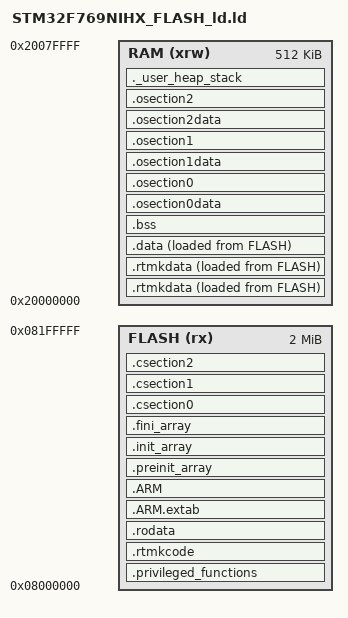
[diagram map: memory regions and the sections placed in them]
/*
******************************************************************************
**
** @file        : LinkerScript.ld
**
** @author      : Auto-generated by STM32CubeIDE
**
**  Abstract    : Linker script for STM32F769I-EVAL Board embedding STM32F769NIHx Device from stm32f7 series
**                      2048KBytes FLASH
**                      512KBytes RAM
**
**                Set heap size, stack size and stack location according
**                to application requirements.
**
**                Set memory bank area and size if external memory is used
**
**  Target      : STMicroelectronics STM32
**
**  Distribution: The file is distributed as is, without any warranty
**                of any kind.
**
******************************************************************************
** @attention
**
** Copyright (c) 2025 STMicroelectronics.
** All rights reserved.
**
** This software is licensed under terms that can be found in the LICENSE file
** in the root directory of this software component.
** If no LICENSE file comes with this software, it is provided AS-IS.
**
******************************************************************************
*/

/* Entry Point */
ENTRY(Reset_Handler)

/* Memories definition */
MEMORY
{
  RAM    (xrw)    : ORIGIN = 0x20000000,   LENGTH = 512K
  FLASH    (rx)    : ORIGIN = 0x8000000,   LENGTH = 2048K
}

/* Highest address of the user mode stack */
_estack = ORIGIN(RAM) + LENGTH(RAM); /* end of "RAM" Ram type memory */

_Min_Heap_Size = 0x400; /* required amount of heap */
_Min_Stack_Size = 0x400; /* required amount of stack */

__privileged_functions_region_size__ = 0x100000;  /* 1 MB */
__privileged_functions_region_end__  = ORIGIN(FLASH) + __privileged_functions_region_size__;

__rtmk_code_region_size__ = 0x4000;  /* 16 KB */
__rtmk_code_region_end__  = __privileged_functions_region_end__ + __rtmk_code_region_size__;

__rtmkdata_region_size__ = 0x2000;             /* 8 KB */
__rtmk_data_region_end__  =  ORIGIN(RAM) + __rtmkdata_region_size__;

/* Sections */
SECTIONS
{
  .privileged_functions :
  {
     . = ALIGN(4);
     KEEP(*(.isr_vector)) /* Startup code */
    . = ALIGN(4);
    *(.text)           /* .text sections (code) */
    *(.text*)          /* .text* sections (code) */
    *(.glue_7)         /* glue arm to thumb code */
    *(.glue_7t)        /* glue thumb to arm code */
    *(.eh_frame)
    KEEP (*(.init))
    KEEP (*(.fini))
    . = ALIGN(4);
   . = __privileged_functions_region_end__;
    _etext = .;        /* define a global symbols at end of code */

  } >FLASH

    .rtmkcode :
  {
    _srtmkcode = .;
    . = ALIGN(4);
    *libc_a*:(.text*)
    *libc.a:(.text*)
    *libm.a:(.text*)
    *libstdc++.a:(.text*)
    *(.rtmkcode)           /* .text sections (code) */
    *(.rtmkcode*)          /* .text* sections (code) */
    *(.glue_7)         /* glue arm to thumb code */
    *(.glue_7t)        /* glue thumb to arm code */
    *(.eh_frame)
    KEEP (*(.init))
    KEEP (*(.fini))

    . = ALIGN(4);
    _etext = .;        /* define a global symbols at end of code */
    _ertmkcode = .;
    . = __rtmk_code_region_end__;
  } >FLASH


  .rtmkdata : 
  { 
      _srtmkdata  = .;      /* start address symbol */
      _srtmkdata2 = .;
      . = ALIGN(4);
      *(privileged_data)
      *(.rtmkdata)         /* all objects with section ".rtmkdata" */
      . = ALIGN(4);
      _ertmkdata = .;      /* end address symbol */
      . = __rtmk_data_region_end__;
      _szrtmkdata = _ertmkdata - _srtmkdata;
  } >RAM AT> FLASH

  _lrtmkdata = LOADADDR(.rtmkdata);

  /* Constant data into "FLASH" Rom type memory */
  .rodata :
  {
    . = ALIGN(4);
    *(.rodata)         /* .rodata sections (constants, strings, etc.) */
    *(.rodata*)        /* .rodata* sections (constants, strings, etc.) */
    . = ALIGN(4);
  } >FLASH

  .ARM.extab : /* The "READONLY" keyword is only supported in GCC11 and later, remove it if using GCC10 or earlier. */
  {
    . = ALIGN(4);
    *(.ARM.extab* .gnu.linkonce.armextab.*)
    . = ALIGN(4);
  } >FLASH

  .ARM : /* The "READONLY" keyword is only supported in GCC11 and later, remove it if using GCC10 or earlier. */
  {
    . = ALIGN(4);
    __exidx_start = .;
    *(.ARM.exidx*)
    __exidx_end = .;
    . = ALIGN(4);
  } >FLASH

  .preinit_array : /* The "READONLY" keyword is only supported in GCC11 and later, remove it if using GCC10 or earlier. */
  {
    . = ALIGN(4);
    PROVIDE_HIDDEN (__preinit_array_start = .);
    KEEP (*(.preinit_array*))
    PROVIDE_HIDDEN (__preinit_array_end = .);
    . = ALIGN(4);
  } >FLASH

  .init_array : /* The "READONLY" keyword is only supported in GCC11 and later, remove it if using GCC10 or earlier. */
  {
    . = ALIGN(4);
    PROVIDE_HIDDEN (__init_array_start = .);
    KEEP (*(SORT(.init_array.*)))
    KEEP (*(.init_array*))
    PROVIDE_HIDDEN (__init_array_end = .);
    . = ALIGN(4);
  } >FLASH

  .fini_array : /* The "READONLY" keyword is only supported in GCC11 and later, remove it if using GCC10 or earlier. */
  {
    . = ALIGN(4);
    PROVIDE_HIDDEN (__fini_array_start = .);
    KEEP (*(SORT(.fini_array.*)))
    KEEP (*(.fini_array*))
    PROVIDE_HIDDEN (__fini_array_end = .);
    . = ALIGN(4);
  } >FLASH

  .rtmkdata :
  {
      _srtmkdata = .;      /* start address symbol */
      *(.rtmkdata)         /* all objects with section ".rtmkdata" */
      _ertmkdata = .;      /* end address symbol */
  } >RAM AT> FLASH

  _lrtmkdata = LOADADDR(.rtmkdata);

  /* Used by the startup to initialize data */
  _sidata = LOADADDR(.data);

  /* Initialized data sections into "RAM" Ram type memory */
  .data :
  {
    . = ALIGN(4);
    _sdata = .;        /* create a global symbol at data start */
    *(.data)           /* .data sections */
    *(.data*)          /* .data* sections */
    *(.RamFunc)        /* .RamFunc sections */
    *(.RamFunc*)       /* .RamFunc* sections */

    . = ALIGN(4);
    _edata = .;        /* define a global symbol at data end */

  } >RAM AT> FLASH


  /* Uninitialized data section into "RAM" Ram type memory */
  . = ALIGN(4);
  .bss :
  {
    /* This is used by the startup in order to initialize the .bss section */
    _sbss = .;         /* define a global symbol at bss start */
    __bss_start__ = _sbss;
    *(.bss)
    *(.bss*)
    *(COMMON)

    . = ALIGN(4);
    _ebss = .;         /* define a global symbol at bss end */
    __bss_end__ = _ebss;
  } >RAM

COMPARTMENT_DATA_START = LOADADDR(.data) + SIZEOF(.data); 
COMPARTMENT_DATA_COUNTER = 0;
  .osection0data : AT (COMPARTMENT_DATA_START + COMPARTMENT_DATA_COUNTER) 
  { . = ALIGN(4); 
		_sosection0data = .; 
  *(.osection0data)		   /* .data sections. */
  . = ALIGN(4); 
  _eosection0data = .;
} > RAM 
COMPARTMENT_DATA_COUNTER = COMPARTMENT_DATA_COUNTER + SIZEOF(.osection0data); 
_sosection0datal = LOADADDR(.osection0data);
  .osection0 :
  {
	  . = ALIGN(4);
	  _sosection0 = .;
	  *(.osection0)
	  . = ALIGN(4);
	  _eosection0 = .;
_szosection0 = _eosection0 - _sosection0data;  }  > RAM 
  .osection1data : AT (COMPARTMENT_DATA_START + COMPARTMENT_DATA_COUNTER) 
  { . = ALIGN(4); 
		_sosection1data = .; 
  *(.osection1data)		   /* .data sections. */
  . = ALIGN(4); 
  _eosection1data = .;
} > RAM 
COMPARTMENT_DATA_COUNTER = COMPARTMENT_DATA_COUNTER + SIZEOF(.osection1data); 
_sosection1datal = LOADADDR(.osection1data);
  .osection1 :
  {
	  . = ALIGN(4);
	  _sosection1 = .;
	  *(.osection1)
	  . = ALIGN(4);
	  _eosection1 = .;
_szosection1 = _eosection1 - _sosection1data;  }  > RAM 
  .osection2data : AT (COMPARTMENT_DATA_START + COMPARTMENT_DATA_COUNTER) 
  { . = ALIGN(4); 
		_sosection2data = .; 
  *(.osection2data)		   /* .data sections. */
  . = ALIGN(4); 
  _eosection2data = .;
} > RAM 
COMPARTMENT_DATA_COUNTER = COMPARTMENT_DATA_COUNTER + SIZEOF(.osection2data); 
_sosection2datal = LOADADDR(.osection2data);
  .osection2 :
  {
	  . = ALIGN(4);
	  _sosection2 = .;
	  *(.osection2)
	  . = ALIGN(4);
	  _eosection2 = .;
_szosection2 = _eosection2 - _sosection2data;  }  > RAM 
	
CODE_SECTIONS_START = LOADADDR(.osection2data) + SIZEOF(.osection2data);
COMPARTMENT_CODE_COUNTER = 0;
  .csection0 (CODE_SECTIONS_START + COMPARTMENT_CODE_COUNTER) : AT(CODE_SECTIONS_START + COMPARTMENT_CODE_COUNTER)
  {
_scsection0 = .;
	  . = ALIGN(4);
	  *(.csection0)
	  . = ALIGN(4);
_ecsection0 = .;
_szcsection0 = _ecsection0 - _scsection0;  } > FLASH 
COMPARTMENT_CODE_COUNTER = COMPARTMENT_CODE_COUNTER + SIZEOF(.csection0); 
  .csection1 (CODE_SECTIONS_START + COMPARTMENT_CODE_COUNTER) : AT(CODE_SECTIONS_START + COMPARTMENT_CODE_COUNTER)
  {
_scsection1 = .;
	  . = ALIGN(4);
	  *(.csection1)
	  . = ALIGN(4);
_ecsection1 = .;
_szcsection1 = _ecsection1 - _scsection1;  } > FLASH 
COMPARTMENT_CODE_COUNTER = COMPARTMENT_CODE_COUNTER + SIZEOF(.csection1); 
  .csection2 (CODE_SECTIONS_START + COMPARTMENT_CODE_COUNTER) : AT(CODE_SECTIONS_START + COMPARTMENT_CODE_COUNTER)
  {
_scsection2 = .;
	  . = ALIGN(4);
	  *(.csection2)
	  . = ALIGN(4);
_ecsection2 = .;
_szcsection2 = _ecsection2 - _scsection2;  } > FLASH 
COMPARTMENT_CODE_COUNTER = COMPARTMENT_CODE_COUNTER + SIZEOF(.csection2); 

  /* User_heap_stack section, used to check that there is enough "RAM" Ram  type memory left */
  ._user_heap_stack :
  {
    . = ALIGN(8);
    PROVIDE ( end = . );
    PROVIDE ( _end = . );
    . = . + _Min_Heap_Size;
    . = . + _Min_Stack_Size;
    . = ALIGN(8);
  } >RAM

  /* Remove information from the compiler libraries */
  /DISCARD/ :
  {
    libc.a ( * )
    libm.a ( * )
    libgcc.a ( * )
  }

  .ARM.attributes 0 : { *(.ARM.attributes) }
}
